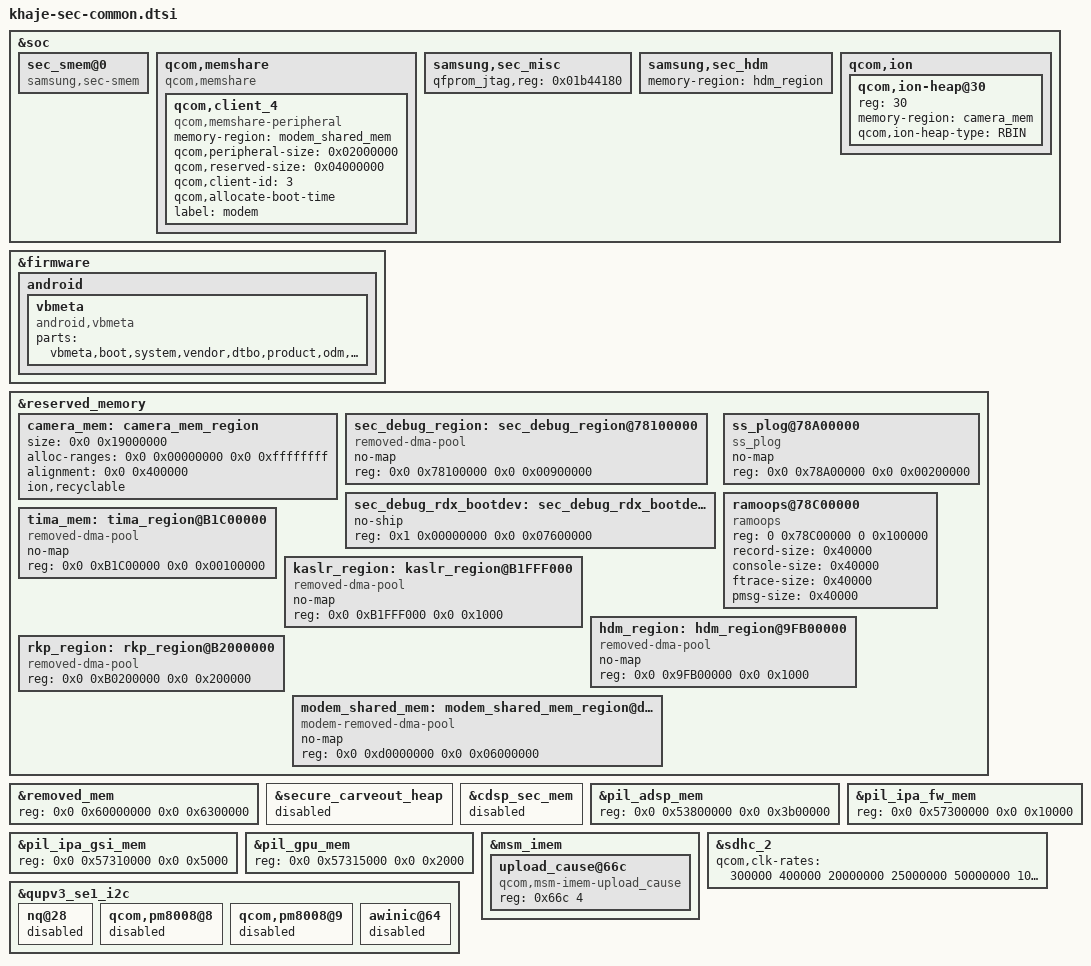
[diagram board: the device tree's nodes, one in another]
/* Copyright (c) 2019, The Linux Foundation. All rights reserved.
 *
 * This program is free software; you can redistribute it and/or modify
 * it under the terms of the GNU General Public License version 2 and
 * only version 2 as published by the Free Software Foundation.
 *
 * This program is distributed in the hope that it will be useful,
 * but WITHOUT ANY WARRANTY; without even the implied warranty of
 * MERCHANTABILITY or FITNESS FOR A PARTICULAR PURPOSE.  See the
 * GNU General Public License for more details.
 */

#include "khaje-sec-uart-common.dtsi"
#include "khaje-sec-dcc-common.dtsi"
#include "khaje-sec-usb-common.dtsi"
#include "khaje-sec-argos-common.dtsi"

&soc {
	sec_smem@0 {
		compatible = "samsung,sec-smem";
		status = "okay";
	};

	qcom,memshare {
		compatible = "qcom,memshare";

		qcom,client_4 {
					compatible = "qcom,memshare-peripheral";
					memory-region = <&modem_shared_mem>;
					qcom,peripheral-size = <0x02000000>;
					qcom,reserved-size = <0x04000000>;
					qcom,client-id = <3>;
					qcom,allocate-boot-time;
					label = "modem";
		};
	};

	samsung,sec_misc {
		qfprom_jtag,reg = <0x01b44180>;
	};

	samsung,sec_hdm {
		memory-region = <&hdm_region>;
	};

};

&firmware {
	android {
		vbmeta {
			compatible = "android,vbmeta";
			parts = "vbmeta,boot,system,vendor,dtbo,product,odm,prism,optics,vbmeta_system,recovery,abl,xbl,tz,hyp";
		};
	};
};

&soc {
	qcom,ion {
		qcom,ion-heap@30 { /* CAMERA HEAP */
			reg = <30>;
			memory-region = <&camera_mem>;
			qcom,ion-heap-type = "RBIN";
		};
	};
};

&reserved_memory {
	camera_mem: camera_mem_region {
		size = <0x0 0x19000000>;
		alloc-ranges = <0x0 0x00000000 0x0 0xffffffff>;
		alignment = <0x0 0x400000>;
		ion,recyclable;
	};

	/* CONFIG_SEC_DEBUG reserves 9MB */
	sec_debug_region: sec_debug_region@78100000 {
		compatible = "removed-dma-pool";
		no-map;
		reg = <0x0 0x78100000 0x0 0x00900000>;
	};

	sec_debug_rdx_bootdev: sec_debug_rdx_bootdev@0 {
		no-ship;
		reg = <0x1 0x00000000 0x0 0x07600000>;
	};

	ss_plog@78A00000 {
		compatible = "ss_plog";
		no-map;
		reg = <0x0 0x78A00000 0x0 0x00200000>;
	};

	ramoops@78C00000 {
		compatible = "ramoops";
		reg = <0 0x78C00000 0 0x100000>;
		record-size = <0x40000>;
		console-size = <0x40000>;
		ftrace-size = <0x40000>;
		pmsg-size = <0x40000>;
	};

	/*to reserve 1MB for TIMA */
	tima_mem: tima_region@B1C00000 {
		compatible = "removed-dma-pool";
		no-map;
		reg = <0x0 0xB1C00000 0x0 0x00100000>;
	};

	/* Kaslr offset reserve */
	kaslr_region: kaslr_region@B1FFF000 {
		compatible = "removed-dma-pool";
		no-map;
		reg = <0x0 0xB1FFF000 0x0 0x1000>;
	};

	hdm_region: hdm_region@9FB00000 {
		compatible = "removed-dma-pool";
		no-map;
		reg = <0x0 0x9FB00000 0x0 0x1000>;
	};

	/* rkp_region reserves for RKP */
	/* CAUTION: DO NOT reserve 0xB1000000 ~ 0xB2800000 region for RKP reserved at the runtime */
	rkp_region: rkp_region@B2000000 {
		compatible = "removed-dma-pool";
		reg = <0x0 0xB0200000 0x0 0x200000>;
	};

	modem_shared_mem: modem_shared_mem_region@d0000000 {
		compatible = "modem-removed-dma-pool";
		no-map;
		reg = <0x0 0xd0000000 0x0 0x06000000>;
	};
};

&removed_mem {
	reg = <0x0 0x60000000 0x0 0x6300000>;
};

/* disable QC CDSPsec memory region */
&secure_carveout_heap {
	status = "disabled";
};
&cdsp_sec_mem {
	status = "disabled";
};

&pil_adsp_mem {
	reg = <0x0 0x53800000 0x0 0x3b00000>;
};
&pil_ipa_fw_mem {
	reg = <0x0 0x57300000 0x0 0x10000>;
};
&pil_ipa_gsi_mem {
	reg = <0x0 0x57310000 0x0 0x5000>;
};
&pil_gpu_mem {
	reg = <0x0 0x57315000 0x0 0x2000>;
};

&msm_imem {
 	upload_cause@66c {
 		compatible = "qcom,msm-imem-upload_cause";
 		reg = <0x66c 4>;
 	};
};

/* disabled QC NFC, PM8008, AW2016 LED */
&qupv3_se1_i2c {
	nq@28 {
		status = "disabled";
	};

	qcom,pm8008@8 {
		status = "disabled";
	};

	qcom,pm8008@9 {
		status = "disabled";
	};

	awinic@64 {
		status = "disabled";
	};
};

&sdhc_2 {
	qcom,clk-rates = <300000 400000 20000000 25000000
		50000000 100000000 202000000>;
};
